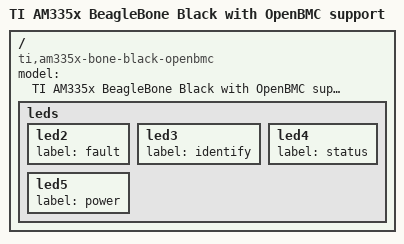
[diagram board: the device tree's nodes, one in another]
// SPDX-License-Identifier: GPL-2.0-only
/*
 * Copyright (C) 2024 Ryan Agius - ryagius17@gmail.com
 */
/dts-v1/;

#include "am335x-boneblack.dts"

/ {
	model = "TI AM335x BeagleBone Black with OpenBMC support";
	compatible = "ti,am335x-bone-black-openbmc", "ti,am335x-bone-black", "ti,am335x-bone", "ti,am33xx";
};

// rename LEDs to a more BCM appropriate naming scheme
/ {
    leds {
        // USR0
        led2 {
            label = "fault";
            /delete-property/ linux,default-trigger;
        };
        // USR1
		led3 {
            label = "identify";
            /delete-property/ linux,default-trigger;
        };
        // USR2
		led4 {
            label = "status";
            /delete-property/ linux,default-trigger;
        };
        // USR3
		led5 {
            label = "power";
            /delete-property/ linux,default-trigger;
        };
    };
};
